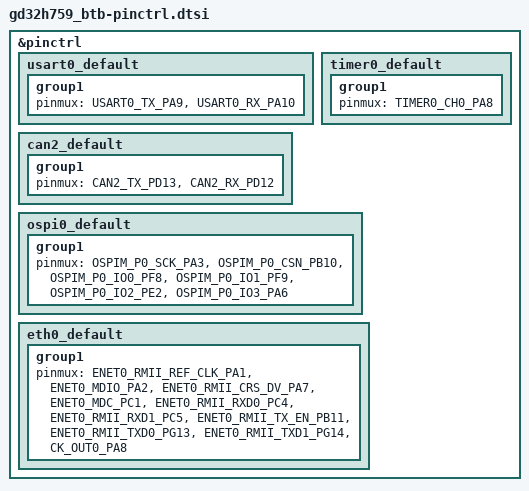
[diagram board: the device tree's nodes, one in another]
/*
 * Copyright (c) 2026 GD32H7xx Zephyr bring-up
 * SPDX-License-Identifier: Apache-2.0
 */

#include <dt-bindings/pinctrl/gd32h759xx-pinctrl.h>

&pinctrl {
	usart0_default: usart0_default {
		group1 {
			pinmux = <USART0_TX_PA9>, <USART0_RX_PA10>;
		};
	};

	timer0_default: timer0_default {
		group1 {
			pinmux = <TIMER0_CH0_PA8>;
		};
	};

	can2_default: can2_default {
		group1 {
			pinmux = <CAN2_TX_PD13>, <CAN2_RX_PD12>;
		};
	};

	/* OSPI0 port 0 to the on-board GD25Q64 NOR flash (U7) */
	ospi0_default: ospi0_default {
		group1 {
			pinmux = <OSPIM_P0_SCK_PA3>, <OSPIM_P0_CSN_PB10>,
				 <OSPIM_P0_IO0_PF8>, <OSPIM_P0_IO1_PF9>,
				 <OSPIM_P0_IO2_PE2>, <OSPIM_P0_IO3_PA6>;
		};
	};

	/* ENET0 RMII to the LAN8720A PHY plus the CK_OUT0 50MHz reference
	 * clock the PHY needs on its CLKIN pin (driver programs RCU_CFG2) */
	eth0_default: eth0_default {
		group1 {
			pinmux = <ENET0_RMII_REF_CLK_PA1>, <ENET0_MDIO_PA2>,
				 <ENET0_RMII_CRS_DV_PA7>, <ENET0_MDC_PC1>,
				 <ENET0_RMII_RXD0_PC4>, <ENET0_RMII_RXD1_PC5>,
				 <ENET0_RMII_TX_EN_PB11>,
				 <ENET0_RMII_TXD0_PG13>,
				 <ENET0_RMII_TXD1_PG14>, <CK_OUT0_PA8>;
		};
	};
};
